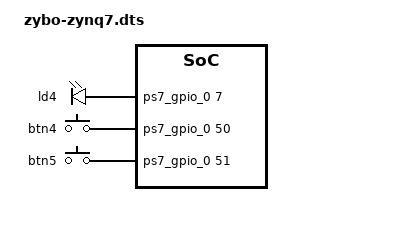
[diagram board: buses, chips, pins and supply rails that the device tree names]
/dts-v1/;
/include/ "zynq7-base.dtsi"
/include/ "zybo-zynq7-board.dtsi"
/ {
	leds {
		compatible = "gpio-leds";
		ld4 {
			label = "ld4";
			linux,default-trigger = "heartbeat";
			gpios = <&ps7_gpio_0 7 0>;
		} ;
	} ;
	gpio-keys {
		compatible = "gpio-keys";
		btn4 {
			label = "btn4";
			gpios = <&ps7_gpio_0 50 0>;
			linux,code = <28>; /* enter key */
		};
		btn5 {
			label = "btn5";
			gpios = <&ps7_gpio_0 51 0>;
			linux,code = <1>; /* esc key */
		};
	} ;
} ;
